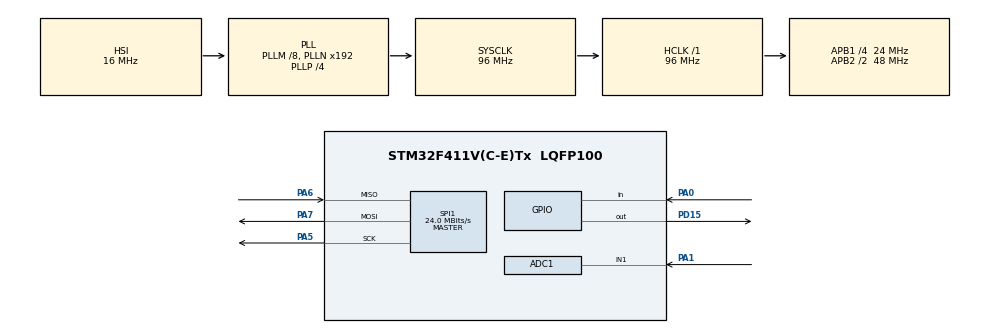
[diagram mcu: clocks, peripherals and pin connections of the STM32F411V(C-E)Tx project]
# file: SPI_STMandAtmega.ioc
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ADC1.Channel-0\#ChannelRegularConversion=ADC_CHANNEL_1
ADC1.ContinuousConvMode=ENABLE
ADC1.NbrOfConversionFlag=1
ADC1.Rank-0\#ChannelRegularConversion=1
ADC1.SamplingTime-0\#ChannelRegularConversion=ADC_SAMPLETIME_3CYCLES
ADC1.master=1
Mcu.Family=STM32F4
Mcu.Name=STM32F411V(C-E)Tx
Mcu.Package=LQFP100
NVIC.ADC_IRQn=true\:0\:0\:false\:false\:true\:true\:true\:true
NVIC.PriorityGroup=NVIC_PRIORITYGROUP_0
NVIC.SPI1_IRQn=true\:0\:0\:false\:false\:true\:true\:true\:true
PA0-WKUP.Signal=GPIO_Input
PA1.Signal=ADCx_IN1
PA5.Mode=Full_Duplex_Master
PA5.Signal=SPI1_SCK
PA6.Mode=Full_Duplex_Master
PA6.Signal=SPI1_MISO
PA7.Mode=Full_Duplex_Master
PA7.Signal=SPI1_MOSI
PD15.Signal=GPIO_Output
ProjectManager.HeapSize=0x200
ProjectManager.StackSize=0x400
ProjectManager.TargetToolchain=STM32CubeIDE
RCC.48MHZClocksFreq_Value=48000000
RCC.AHBFreq_Value=96000000
RCC.APB1CLKDivider=RCC_HCLK_DIV4
RCC.APB1Freq_Value=24000000
RCC.APB1TimFreq_Value=48000000
RCC.APB2CLKDivider=RCC_HCLK_DIV2
RCC.APB2Freq_Value=48000000
RCC.APB2TimFreq_Value=96000000
RCC.CortexFreq_Value=96000000
RCC.HCLKFreq_Value=96000000
RCC.HSE_VALUE=8000000
RCC.HSI_VALUE=16000000
RCC.LSE_VALUE=32768
RCC.PLLI2SM=5
RCC.PLLI2SN=200
RCC.PLLM=8
RCC.PLLP=RCC_PLLP_DIV4
RCC.PLLQ=8
RCC.SYSCLKFreq_VALUE=96000000
RCC.SYSCLKSource=RCC_SYSCLKSOURCE_PLLCLK
RCC.VCOOutputFreq_Value=384000000
SH.ADCx_IN1.0=ADC1_IN1,IN1
SPI1.CalculateBaudRate=24.0 MBits/s
SPI1.Direction=SPI_DIRECTION_2LINES
SPI1.Mode=SPI_MODE_MASTER
SPI1.VirtualType=VM_MASTER
board=STM32F411E-DISCO

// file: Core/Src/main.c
/* USER CODE BEGIN Header */
/**
  ******************************************************************************
  * @file           : main.c
  * @brief          : Main program body
  ******************************************************************************
  * @attention
  *
  * Copyright (c) 2025 STMicroelectronics.
  * All rights reserved.
  *
  * This software is licensed under terms that can be found in the LICENSE file
  * in the root directory of this software component.
  * If no LICENSE file comes with this software, it is provided AS-IS.
  *
  ******************************************************************************
  */
/* USER CODE END Header */
#include "main.h"

ADC_HandleTypeDef hadc1;
SPI_HandleTypeDef hspi1;

/* USER CODE BEGIN PV */
uint8_t txData = 0;
uint32_t adcValue = 0; // 12-bit ADC value
/* USER CODE END PV */

void SystemClock_Config(void);

/**
  * @brief  Initialize GPIO pins for SPI and other peripherals.
  * @retval None
  */
static void MX_GPIO_Init(void);

/**
  * @brief  Initialize SPI1 peripheral.
  * @retval None
  */
static void MX_SPI1_Init(void);

/**
  * @brief  Initialize ADC1 peripheral.
  * @retval None
  */
static void MX_ADC1_Init(void);

int main(void)
{

  /* MCU Configuration--------------------------------------------------------*/

  /* Reset of all peripherals, Initializes the Flash interface and the Systick. */
  HAL_Init();

  /* Configure the system clock */
  SystemClock_Config();

  /* Initialize all configured peripherals */
  MX_GPIO_Init();
  MX_SPI1_Init();
  MX_ADC1_Init();

  /* Infinite loop */
  /* USER CODE BEGIN WHILE */
  HAL_GPIO_WritePin(GPIOA, GPIO_PIN_4, GPIO_PIN_SET); // SS HIGH (not select slave)
  while (1)
  {
    /* USER CODE END WHILE */

    /* USER CODE BEGIN 3 */
    // Read ADC (12-bit: 0-4095)
    HAL_ADC_Start(&hadc1);
    HAL_ADC_PollForConversion(&hadc1, 100);
    adcValue = HAL_ADC_GetValue(&hadc1);

    // Convert to 8-bit for SPI transmit (0-255)
    txData = adcValue / 16; // 4095/255 ≈ 16

    HAL_GPIO_WritePin(GPIOA, GPIO_PIN_4, GPIO_PIN_RESET); // SS LOW (select slave)
    HAL_SPI_Transmit(&hspi1, &txData, 1, 100);
    HAL_GPIO_WritePin(GPIOA, GPIO_PIN_4, GPIO_PIN_SET);   // SS HIGH (not select slave)

    HAL_Delay(100);
    /* USER CODE END 3 */
  }
}

void SystemClock_Config(void)
{
  RCC_OscInitTypeDef RCC_OscInitStruct = {0};
  RCC_ClkInitTypeDef RCC_ClkInitStruct = {0};

  /* Configure the main internal regulator output voltage */
  __HAL_RCC_PWR_CLK_ENABLE();
  __HAL_PWR_VOLTAGESCALING_CONFIG(PWR_REGULATOR_VOLTAGE_SCALE1);

  /* Initializes the RCC Oscillators according to the specified parameters */
  RCC_OscInitStruct.OscillatorType = RCC_OSCILLATORTYPE_HSI;
  RCC_OscInitStruct.HSIState = RCC_HSI_ON;
  RCC_OscInitStruct.HSICalibrationValue = RCC_HSICALIBRATION_DEFAULT;
  RCC_OscInitStruct.PLL.PLLState = RCC_PLL_ON;
  RCC_OscInitStruct.PLL.PLLSource = RCC_PLLSOURCE_HSI;
  RCC_OscInitStruct.PLL.PLLM = 8;
  RCC_OscInitStruct.PLL.PLLN = 192;
  RCC_OscInitStruct.PLL.PLLP = RCC_PLLP_DIV4;
  RCC_OscInitStruct.PLL.PLLQ = 8;
  if (HAL_RCC_OscConfig(&RCC_OscInitStruct) != HAL_OK)
  {
    Error_Handler();
  }

  /* Initializes the CPU, AHB and APB buses clocks */
  RCC_ClkInitStruct.ClockType = RCC_CLOCKTYPE_HCLK | RCC_CLOCKTYPE_SYSCLK
                              | RCC_CLOCKTYPE_PCLK1 | RCC_CLOCKTYPE_PCLK2;
  RCC_ClkInitStruct.SYSCLKSource = RCC_SYSCLKSOURCE_PLLCLK;
  RCC_ClkInitStruct.AHBCLKDivider = RCC_SYSCLK_DIV1;
  RCC_ClkInitStruct.APB1CLKDivider = RCC_HCLK_DIV4;
  RCC_ClkInitStruct.APB2CLKDivider = RCC_HCLK_DIV2;

  if (HAL_RCC_ClockConfig(&RCC_ClkInitStruct, FLASH_LATENCY_3) != HAL_OK)
  {
    Error_Handler();
  }
}

/**
  * @brief  Initialize ADC1 peripheral.
  *         Configures ADC1 for single channel, 12-bit resolution.
  * @retval None
  */
static void MX_ADC1_Init(void)
{
  ADC_ChannelConfTypeDef sConfig = {0};

  /* Configure the global features of the ADC (Clock, Resolution, Data Alignment and number of conversion) */
  hadc1.Instance = ADC1;
  hadc1.Init.ClockPrescaler = ADC_CLOCK_SYNC_PCLK_DIV4;
  hadc1.Init.Resolution = ADC_RESOLUTION_12B;
  hadc1.Init.ScanConvMode = DISABLE;
  hadc1.Init.ContinuousConvMode = DISABLE;
  hadc1.Init.DiscontinuousConvMode = DISABLE;
  hadc1.Init.ExternalTrigConvEdge = ADC_EXTERNALTRIGCONVEDGE_NONE;
  hadc1.Init.ExternalTrigConv = ADC_SOFTWARE_START;
  hadc1.Init.DataAlign = ADC_DATAALIGN_RIGHT;
  hadc1.Init.NbrOfConversion = 1;
  hadc1.Init.DMAContinuousRequests = DISABLE;
  hadc1.Init.EOCSelection = ADC_EOC_SINGLE_CONV;
  if (HAL_ADC_Init(&hadc1) != HAL_OK)
  {
    Error_Handler();
  }

  /* Configure for the selected ADC regular channel its corresponding rank in the sequencer and its sample time */
  sConfig.Channel = ADC_CHANNEL_1;
  sConfig.Rank = 1;
  sConfig.SamplingTime = ADC_SAMPLETIME_3CYCLES;
  if (HAL_ADC_ConfigChannel(&hadc1, &sConfig) != HAL_OK)
  {
    Error_Handler();
  }
}

/**
  * @brief  Initialize SPI1 peripheral.
  *         Configures SPI1 as master, 8-bit, software NSS.
  * @retval None
  */
static void MX_SPI1_Init(void)
{
  /* SPI1 parameter configuration */
  hspi1.Instance = SPI1;
  hspi1.Init.Mode = SPI_MODE_MASTER;
  hspi1.Init.Direction = SPI_DIRECTION_2LINES;
  hspi1.Init.DataSize = SPI_DATASIZE_8BIT;
  hspi1.Init.CLKPolarity = SPI_POLARITY_LOW;
  hspi1.Init.CLKPhase = SPI_PHASE_1EDGE;
  hspi1.Init.NSS = SPI_NSS_SOFT;
  hspi1.Init.BaudRatePrescaler = SPI_BAUDRATEPRESCALER_64;
  hspi1.Init.FirstBit = SPI_FIRSTBIT_MSB;
  hspi1.Init.TIMode = SPI_TIMODE_DISABLE;
  hspi1.Init.CRCCalculation = SPI_CRCCALCULATION_DISABLE;
  hspi1.Init.CRCPolynomial = 10;
  if (HAL_SPI_Init(&hspi1) != HAL_OK)
  {
    Error_Handler();
  }
}

/**
  * @brief  Initialize GPIO pins for SPI and other peripherals.
  *         Configures PA4 as manual NSS, PA5/6/7 as SPI1 AF, and other used pins.
  * @retval None
  */
static void MX_GPIO_Init(void)
{
  GPIO_InitTypeDef GPIO_InitStruct = {0};

  /* GPIO Ports Clock Enable */
  __HAL_RCC_GPIOA_CLK_ENABLE();
  __HAL_RCC_GPIOD_CLK_ENABLE();

  /* Configure GPIO pin Output Level */
  HAL_GPIO_WritePin(GPIOD, GPIO_PIN_15, GPIO_PIN_RESET);

  /* Configure GPIO pin : PA0 */
  GPIO_InitStruct.Pin = GPIO_PIN_0;
  GPIO_InitStruct.Mode = GPIO_MODE_INPUT;
  GPIO_InitStruct.Pull = GPIO_NOPULL;
  HAL_GPIO_Init(GPIOA, &GPIO_InitStruct);

  /* Configure GPIO pin : PD15 */
  GPIO_InitStruct.Pin = GPIO_PIN_15;
  GPIO_InitStruct.Mode = GPIO_MODE_OUTPUT_PP;
  GPIO_InitStruct.Pull = GPIO_NOPULL;
  GPIO_InitStruct.Speed = GPIO_SPEED_FREQ_LOW;
  HAL_GPIO_Init(GPIOD, &GPIO_InitStruct);

  /*
   * SPI1 pin configuration for STM32F4:
   * - PA4: SPI1_NSS (manual SS, default HIGH)
   * - PA5: SPI1_SCK
   * - PA6: SPI1_MISO
   * - PA7: SPI1_MOSI
   * Only configure Alternate Function for SCK, MISO, MOSI.
   * NSS (PA4) is manual, set as Output Push-Pull.
   */

  // Configure PA4 as manual SS (NSS)
  GPIO_InitStruct.Pin = GPIO_PIN_4;
  GPIO_InitStruct.Mode = GPIO_MODE_OUTPUT_PP;
  GPIO_InitStruct.Pull = GPIO_NOPULL;
  GPIO_InitStruct.Speed = GPIO_SPEED_FREQ_LOW;
  HAL_GPIO_Init(GPIOA, &GPIO_InitStruct);

  // Set default SS HIGH (not select slave)
  HAL_GPIO_WritePin(GPIOA, GPIO_PIN_4, GPIO_PIN_SET);

  // Configure PA5 (SCK), PA6 (MISO), PA7 (MOSI) for SPI1
  GPIO_InitStruct.Mode      = GPIO_MODE_AF_PP;
  GPIO_InitStruct.Pull      = GPIO_NOPULL;
  GPIO_InitStruct.Speed     = GPIO_SPEED_FREQ_VERY_HIGH;
  GPIO_InitStruct.Alternate = GPIO_AF5_SPI1;

  // PA5 - SCK
  GPIO_InitStruct.Pin = GPIO_PIN_5;
  HAL_GPIO_Init(GPIOA, &GPIO_InitStruct);

  // PA6 - MISO
  GPIO_InitStruct.Pin = GPIO_PIN_6;
  HAL_GPIO_Init(GPIOA, &GPIO_InitStruct);

  // PA7 - MOSI
  GPIO_InitStruct.Pin = GPIO_PIN_7;
  HAL_GPIO_Init(GPIOA, &GPIO_InitStruct);
}

void Error_Handler(void)
{
  __disable_irq();
  while (1)
  {
  }
}
